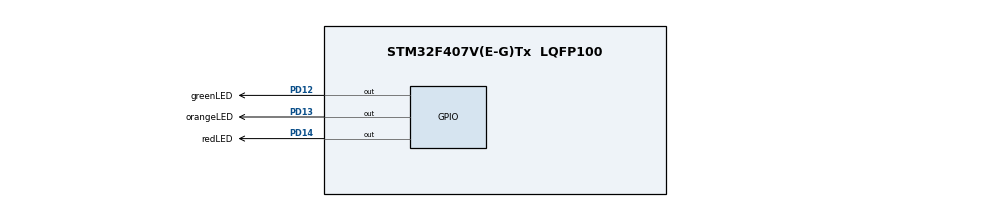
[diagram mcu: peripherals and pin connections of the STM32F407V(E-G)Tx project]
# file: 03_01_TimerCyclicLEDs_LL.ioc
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Mcu.Family=STM32F4
Mcu.Name=STM32F407V(E-G)Tx
Mcu.Package=LQFP100
NVIC.PriorityGroup=NVIC_PRIORITYGROUP_4
PD12.GPIO_Label=greenLED
PD12.Signal=GPIO_Output
PD13.GPIO_Label=orangeLED
PD13.Signal=GPIO_Output
PD14.GPIO_Label=redLED
PD14.Signal=GPIO_Output
ProjectManager.HeapSize=0x200
ProjectManager.StackSize=0x400
ProjectManager.TargetToolchain=STM32CubeIDE
RCC.AHBFreq_Value=16000000
RCC.APB1Freq_Value=16000000
RCC.APB2Freq_Value=16000000
RCC.CortexFreq_Value=16000000
RCC.HSE_VALUE=25000000
RCC.HSI_VALUE=16000000
RCC.LSE_VALUE=32768
RCC.SYSCLKFreq_VALUE=16000000
RCC.VCOOutputFreq_Value=192000000
TIM10.Period=1000
TIM10.Prescaler=16000
VP_TIM10_VS_ClockSourceINT.Mode=Enable_Timer
board=custom

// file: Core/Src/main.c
/* USER CODE BEGIN Header */
/**
  ******************************************************************************
  * @file           : main.c
  * @brief          : Main program body
  ******************************************************************************
  * @attention
  *
  * Copyright (c) 2024 STMicroelectronics.
  * All rights reserved.
  *
  * This software is licensed under terms that can be found in the LICENSE file
  * in the root directory of this software component.
  * If no LICENSE file comes with this software, it is provided AS-IS.
  *
  ******************************************************************************
  */
/* USER CODE END Header */
#include "main.h"

void SystemClock_Config(void);
static void MX_GPIO_Init(void);
static void MX_TIM10_Init(void);

int main(void)
{

  /* USER CODE BEGIN 1 */
	uint32_t status1 = 0;
	uint8_t state = 0;
  /* USER CODE END 1 */

  /* MCU Configuration--------------------------------------------------------*/

  /* Reset of all peripherals, Initializes the Flash interface and the Systick. */
  LL_APB2_GRP1_EnableClock(LL_APB2_GRP1_PERIPH_SYSCFG);
  LL_APB1_GRP1_EnableClock(LL_APB1_GRP1_PERIPH_PWR);

  /* System interrupt init*/
  NVIC_SetPriorityGrouping(NVIC_PRIORITYGROUP_4);

  /* SysTick_IRQn interrupt configuration */
  NVIC_SetPriority(SysTick_IRQn, NVIC_EncodePriority(NVIC_GetPriorityGrouping(),15, 0));

  /* Configure the system clock */
  SystemClock_Config();

  /* Initialize all configured peripherals */
  MX_GPIO_Init();
  MX_TIM10_Init();
  /* USER CODE BEGIN 2 */
  LL_TIM_EnableCounter(TIM10);
  TIM10->CCR1 = 200;
  /* USER CODE END 2 */

  /* Infinite loop */
  /* USER CODE BEGIN WHILE */
  while (1)
  {
	  status1 = LL_TIM_IsActiveFlag_CC1(TIM10);
	  if(status1){
		  LL_TIM_ClearFlag_CC1(TIM10);
		  LL_TIM_SetCounter(TIM10, 0);
		  state++;
		  if(state > 2) state = 0;
	  }
	  switch(state){
	  case 0:
		  LL_GPIO_WriteOutputPort(greenLED_GPIO_Port, greenLED_Pin);
		  break;
	  case 1:
		  LL_GPIO_WriteOutputPort(orangeLED_GPIO_Port, orangeLED_Pin);
		  break;
	  case 2:
		  LL_GPIO_WriteOutputPort(redLED_GPIO_Port, redLED_Pin);
	  }

    /* USER CODE END WHILE */

  }
}

void SystemClock_Config(void)
{
  LL_FLASH_SetLatency(LL_FLASH_LATENCY_0);
  while(LL_FLASH_GetLatency()!= LL_FLASH_LATENCY_0)
  {
  }
  LL_PWR_SetRegulVoltageScaling(LL_PWR_REGU_VOLTAGE_SCALE1);
  LL_RCC_HSI_SetCalibTrimming(16);
  LL_RCC_HSI_Enable();

   /* Wait till HSI is ready */
  while(LL_RCC_HSI_IsReady() != 1)
  {

  }
  LL_RCC_SetAHBPrescaler(LL_RCC_SYSCLK_DIV_1);
  LL_RCC_SetAPB1Prescaler(LL_RCC_APB1_DIV_1);
  LL_RCC_SetAPB2Prescaler(LL_RCC_APB2_DIV_1);
  LL_RCC_SetSysClkSource(LL_RCC_SYS_CLKSOURCE_HSI);

   /* Wait till System clock is ready */
  while(LL_RCC_GetSysClkSource() != LL_RCC_SYS_CLKSOURCE_STATUS_HSI)
  {

  }
  LL_Init1msTick(16000000);
  LL_SetSystemCoreClock(16000000);
}

static void MX_TIM10_Init(void)
{

  LL_TIM_InitTypeDef TIM_InitStruct = {0};

  /* Peripheral clock enable */
  LL_APB2_GRP1_EnableClock(LL_APB2_GRP1_PERIPH_TIM10);

  TIM_InitStruct.Prescaler = 16000;
  TIM_InitStruct.CounterMode = LL_TIM_COUNTERMODE_UP;
  TIM_InitStruct.Autoreload = 1000;
  TIM_InitStruct.ClockDivision = LL_TIM_CLOCKDIVISION_DIV1;
  LL_TIM_Init(TIM10, &TIM_InitStruct);
  LL_TIM_DisableARRPreload(TIM10);

}

static void MX_GPIO_Init(void)
{
  LL_GPIO_InitTypeDef GPIO_InitStruct = {0};

  /* GPIO Ports Clock Enable */
  LL_AHB1_GRP1_EnableClock(LL_AHB1_GRP1_PERIPH_GPIOD);

  /**/
  LL_GPIO_ResetOutputPin(GPIOD, greenLED_Pin|orangeLED_Pin|redLED_Pin);

  /**/
  GPIO_InitStruct.Pin = greenLED_Pin|orangeLED_Pin|redLED_Pin;
  GPIO_InitStruct.Mode = LL_GPIO_MODE_OUTPUT;
  GPIO_InitStruct.Speed = LL_GPIO_SPEED_FREQ_LOW;
  GPIO_InitStruct.OutputType = LL_GPIO_OUTPUT_PUSHPULL;
  GPIO_InitStruct.Pull = LL_GPIO_PULL_NO;
  LL_GPIO_Init(GPIOD, &GPIO_InitStruct);

}

void Error_Handler(void)
{
  __disable_irq();
  while (1)
  {
  }
}
